# TM4C1233H6PGE register map
Vendor: Texas Instruments; Series: TM4C; File version: 11073
CPU: CM4 r1p2, little endian, MPU, FPU, 3 interrupt priority bits
Registers are 32-bit, read-write, no defined reset value unless marked. A register's access mark holds for its fields unless they carry their own. Offsets are from the block's base; [hi:lo] are bit positions; {n}, {i} and the like mark numbered series.

## SSI0 — Register map for SSI0 peripheral
Base 0x40008000; register names take the prefix SSI0
Same registers: SSI1 0x40009000 (register names take the prefix SSI1), SSI2 0x4000A000 (register names take the prefix SSI2), SSI3 0x4000B000 (register names take the prefix SSI3)
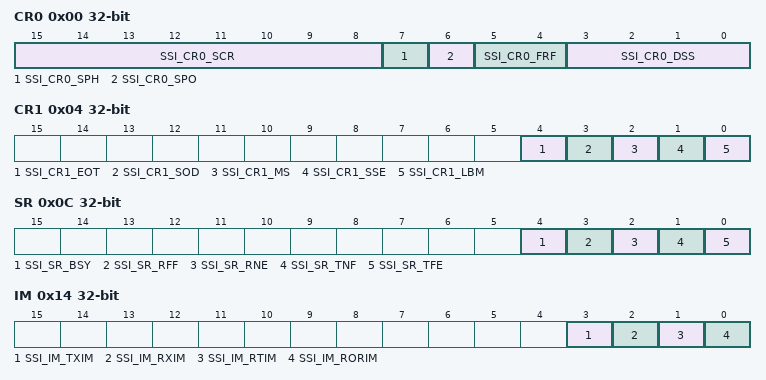
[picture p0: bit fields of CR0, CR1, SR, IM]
0x00 CR0 — SSI Control 0
  [15:8] SSI_CR0_SCR — SSI Serial Clock Rate
  [7] SSI_CR0_SPH — SSI Serial Clock Phase
  [6] SSI_CR0_SPO — SSI Serial Clock Polarity
  [5:4] SSI_CR0_FRF — SSI Frame Format Select
    0=SSI_CR0_FRF_MOTO (Freescale SPI Frame Format); 1=SSI_CR0_FRF_TI (Texas Instruments Synchronous Serial Frame Format); 2=SSI_CR0_FRF_NMW (MICROWIRE Frame Format)
  [3:0] SSI_CR0_DSS — SSI Data Size Select
    {v}={v+1}-bit data (v=3..15)
0x04 CR1 — SSI Control 1
  [4] SSI_CR1_EOT — End of Transmission
  [3] SSI_CR1_SOD — SSI Slave Mode Output Disable
  [2] SSI_CR1_MS — SSI Master/Slave Select
  [1] SSI_CR1_SSE — SSI Synchronous Serial Port Enable
  [0] SSI_CR1_LBM — SSI Loopback Mode
0x08 DR — SSI Data
  [15:0] SSI_DR_DATA — SSI Receive/Transmit Data
0x0C SR — SSI Status
  [4] SSI_SR_BSY — SSI Busy Bit
  [3] SSI_SR_RFF — SSI Receive FIFO Full
  [2] SSI_SR_RNE — SSI Receive FIFO Not Empty
  [1] SSI_SR_TNF — SSI Transmit FIFO Not Full
  [0] SSI_SR_TFE — SSI Transmit FIFO Empty
0x10 CPSR — SSI Clock Prescale
  [7:0] SSI_CPSR_CPSDVSR — SSI Clock Prescale Divisor
0x14 IM — SSI Interrupt Mask
  [3] SSI_IM_TXIM — SSI Transmit FIFO Interrupt Mask
  [2] SSI_IM_RXIM — SSI Receive FIFO Interrupt Mask
  [1] SSI_IM_RTIM — SSI Receive Time-Out Interrupt Mask
  [0] SSI_IM_RORIM — SSI Receive Overrun Interrupt Mask
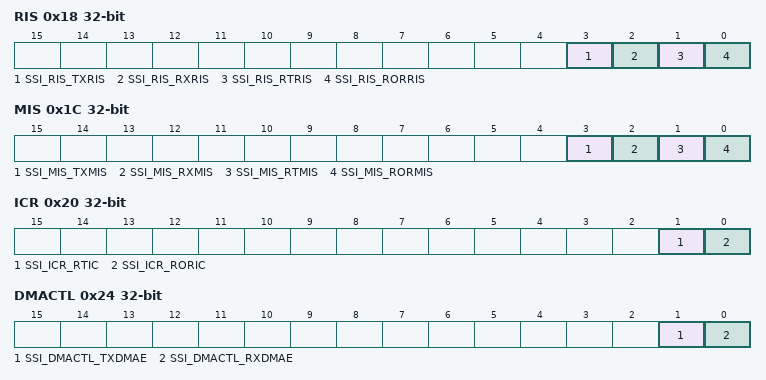
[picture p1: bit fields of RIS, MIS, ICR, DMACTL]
0x18 RIS — SSI Raw Interrupt Status
  [3] SSI_RIS_TXRIS — SSI Transmit FIFO Raw Interrupt Status
  [2] SSI_RIS_RXRIS — SSI Receive FIFO Raw Interrupt Status
  [1] SSI_RIS_RTRIS — SSI Receive Time-Out Raw Interrupt Status
  [0] SSI_RIS_RORRIS — SSI Receive Overrun Raw Interrupt Status
0x1C MIS — SSI Masked Interrupt Status
  [3] SSI_MIS_TXMIS — SSI Transmit FIFO Masked Interrupt Status
  [2] SSI_MIS_RXMIS — SSI Receive FIFO Masked Interrupt Status
  [1] SSI_MIS_RTMIS — SSI Receive Time-Out Masked Interrupt Status
  [0] SSI_MIS_RORMIS — SSI Receive Overrun Masked Interrupt Status
0x20 ICR wo — SSI Interrupt Clear
  [1] SSI_ICR_RTIC — SSI Receive Time-Out Interrupt Clear
  [0] SSI_ICR_RORIC — SSI Receive Overrun Interrupt Clear
0x24 DMACTL — SSI DMA Control
  [1] SSI_DMACTL_TXDMAE — Transmit DMA Enable
  [0] SSI_DMACTL_RXDMAE — Receive DMA Enable
0xFC8 CC — SSI Clock Configuration
  [3:0] SSI_CC_CS — SSI Baud Clock Source
    0=SSI_CC_CS_SYSPLL (Either the system clock (if the PLL bypass is in effect) or the PLL output (default)); 5=SSI_CC_CS_PIOSC (PIOSC)

## EEPROM — Register map for EEPROM peripheral
Base 0x400AF000; register names take the prefix EEPROM
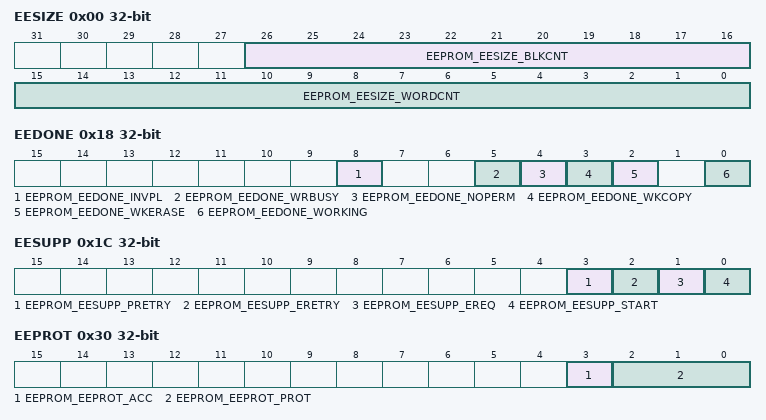
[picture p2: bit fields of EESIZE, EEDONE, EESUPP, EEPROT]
0x00 EESIZE — EEPROM Size Information
  [26:16] EEPROM_EESIZE_BLKCNT — Number of 16-Word Blocks
  [15:0] EEPROM_EESIZE_WORDCNT — Number of 32-Bit Words
0x04 EEBLOCK — EEPROM Current Block
  [15:0] EEPROM_EEBLOCK_BLOCK — Current Block
0x08 EEOFFSET — EEPROM Current Offset
  [3:0] EEPROM_EEOFFSET_OFFSET — Current Address Offset
0x10 EERDWR — EEPROM Read-Write
  [31:0] EEPROM_EERDWR_VALUE — EEPROM Read or Write Data
0x14 EERDWRINC — EEPROM Read-Write with Increment
  [31:0] EEPROM_EERDWRINC_VALUE — EEPROM Read or Write Data with Increment
0x18 EEDONE — EEPROM Done Status
  [8] EEPROM_EEDONE_INVPL — Invalid Program Voltage Level
  [5] EEPROM_EEDONE_WRBUSY — Write Busy
  [4] EEPROM_EEDONE_NOPERM — Write Without Permission
  [3] EEPROM_EEDONE_WKCOPY — Working on a Copy
  [2] EEPROM_EEDONE_WKERASE — Working on an Erase
  [0] EEPROM_EEDONE_WORKING — EEPROM Working
0x1C EESUPP — EEPROM Support Control and Status
  [3] EEPROM_EESUPP_PRETRY — Programming Must Be Retried
  [2] EEPROM_EESUPP_ERETRY — Erase Must Be Retried
  [1] EEPROM_EESUPP_EREQ — Erase Required
  [0] EEPROM_EESUPP_START — Start Erase
0x20 EEUNLOCK — EEPROM Unlock
  [31:0] EEPROM_EEUNLOCK_UNLOCK
0x30 EEPROT — EEPROM Protection
  [3] EEPROM_EEPROT_ACC — Access Control
  [2:0] EEPROM_EEPROT_PROT — Protection Control
    0=EEPROM_EEPROT_PROT_RWNPW (This setting is the default. If there is no password, the block is not protected and is readable and writable); 1=EEPROM_EEPROT_PROT_RWPW (If there is a password, the block is readable or writable only when unlocked); 2=EEPROM_EEPROT_PROT_RONPW (If there is no password, the block is readable, not writable)
{0x34+4i} EEPASS{i} (i=0..2) — EEPROM Password
  [31:0] EEPROM_EEPASS{i}_PASS — Password
0x40 EEINT — EEPROM Interrupt
  [0] EEPROM_EEINT_INT — Interrupt Enable
0x50 EEHIDE — EEPROM Block Hide
  [31:1] EEPROM_EEHIDE_HN — Hide Block
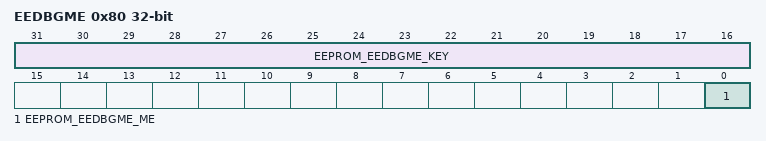
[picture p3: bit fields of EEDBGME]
0x80 EEDBGME — EEPROM Debug Mass Erase
  [31:16] EEPROM_EEDBGME_KEY — Erase Key
  [0] EEPROM_EEDBGME_ME — Mass Erase
0xFC0 PP — EEPROM Peripheral Properties
  [4:0] EEPROM_PP_SIZE — EEPROM Size

## Notices in the file
Software License Agreement
Texas Instruments (TI) is supplying this software for use solely and
exclusively on TI's microcontroller products. The software is owned by
TI and/or its suppliers, and is protected under applicable copyright
laws. You may not combine this software with "viral" open-source
software in order to form a larger program.
THIS SOFTWARE IS PROVIDED "AS IS" AND WITH ALL FAULTS.
NO WARRANTIES, WHETHER EXPRESS, IMPLIED OR STATUTORY, INCLUDING, BUT
NOT LIMITED TO, IMPLIED WARRANTIES OF MERCHANTABILITY AND FITNESS FOR
A PARTICULAR PURPOSE APPLY TO THIS SOFTWARE. TI SHALL NOT, UNDER ANY
CIRCUMSTANCES, BE LIABLE FOR SPECIAL, INCIDENTAL, OR CONSEQUENTIAL
DAMAGES, FOR ANY REASON WHATSOEVER.
